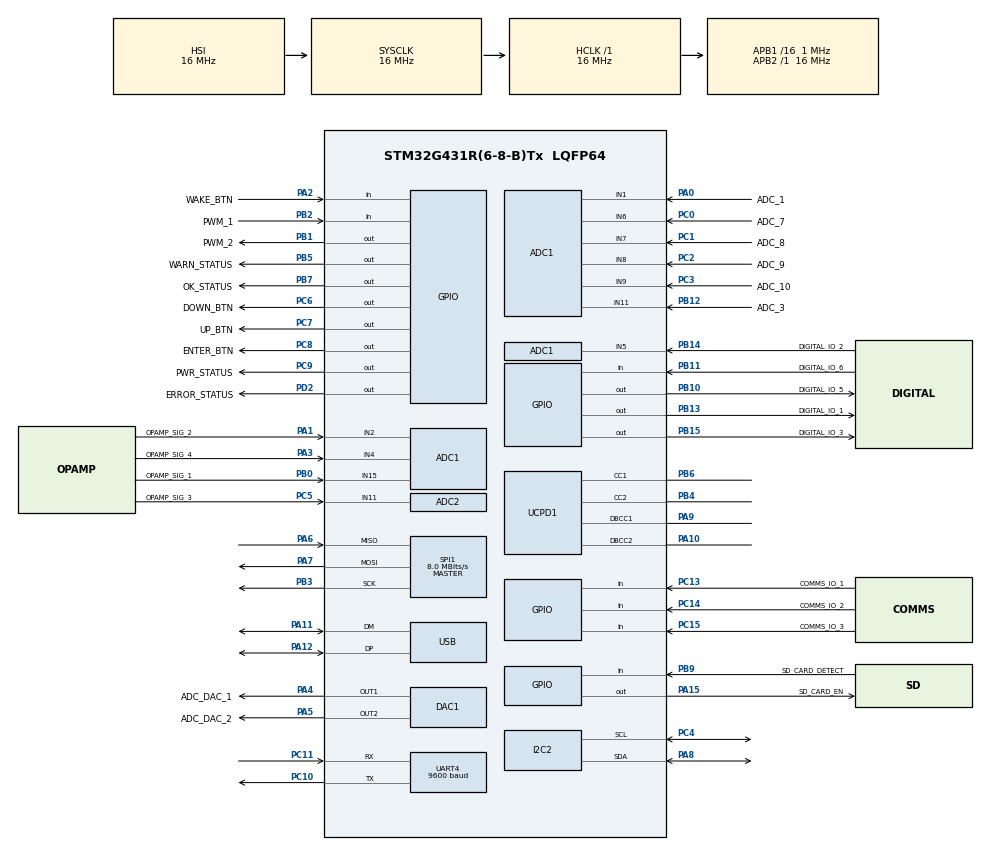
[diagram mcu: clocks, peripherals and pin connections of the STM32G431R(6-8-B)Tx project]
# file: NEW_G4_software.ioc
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ADC1.Channel-0\#ChannelRegularConversion=ADC_CHANNEL_1
ADC1.NbrOfConversionFlag=1
ADC1.OffsetNumber-0\#ChannelRegularConversion=ADC_OFFSET_NONE
ADC1.Rank-0\#ChannelRegularConversion=1
ADC1.SamplingTime-0\#ChannelRegularConversion=ADC_SAMPLETIME_2CYCLES_5
ADC1.master=1
ADC2.Channel-0\#ChannelRegularConversion=ADC_CHANNEL_11
ADC2.NbrOfConversionFlag=1
ADC2.OffsetNumber-0\#ChannelRegularConversion=ADC_OFFSET_NONE
ADC2.Rank-0\#ChannelRegularConversion=1
ADC2.SamplingTime-0\#ChannelRegularConversion=ADC_SAMPLETIME_2CYCLES_5
DAC1.DAC_Channel-DAC_OUT2=DAC_CHANNEL_2
I2C2.Timing=0x00000103
Mcu.Family=STM32G4
Mcu.Name=STM32G431R(6-8-B)Tx
Mcu.Package=LQFP64
NVIC.PriorityGroup=NVIC_PRIORITYGROUP_4
NVIC.USB_LP_IRQn=true\:0\:0\:false\:false\:true\:false\:true\:true
PA0.GPIO_Label=ADC_1
PA0.Mode=IN1-Single-Ended
PA0.Signal=ADC1_IN1
PA1.GPIO_Label=OPAMP_SIG_2
PA1.Mode=IN2-Single-Ended
PA1.Signal=ADC1_IN2
PA10.Mode=EnableDeadBattery
PA10.Signal=UCPD1_DBCC2
PA11.Mode=Device
PA11.Signal=USB_DM
PA12.Mode=Device
PA12.Signal=USB_DP
PA13.Mode=Serial_Wire
PA13.Signal=SYS_JTMS-SWDIO
PA14.Mode=Serial_Wire
PA14.Signal=SYS_JTCK-SWCLK
PA15.GPIO_Label=SD_CARD_EN
PA15.GPIO_ModeDefaultOutputPP=GPIO_MODE_OUTPUT_PP
PA15.GPIO_PuPd=GPIO_NOPULL
PA15.Signal=GPIO_Output
PA2.GPIO_Label=WAKE_BTN
PA2.Signal=GPIO_Input
PA3.GPIO_Label=OPAMP_SIG_4
PA3.Mode=IN4-Single-Ended
PA3.Signal=ADC1_IN4
PA4.GPIO_Label=ADC_DAC_1
PA4.Signal=COMP_DAC11_group
PA5.GPIO_Label=ADC_DAC_2
PA5.Signal=COMP_DAC12_group
PA6.Mode=Full_Duplex_Master
PA6.Signal=SPI1_MISO
PA7.Mode=Full_Duplex_Master
PA7.Signal=SPI1_MOSI
PA8.Mode=I2C
PA8.Signal=I2C2_SDA
PA9.Mode=EnableDeadBattery
PA9.Signal=UCPD1_DBCC1
PB0.GPIO_Label=OPAMP_SIG_1
PB0.Mode=IN15-Single-Ended
PB0.Signal=ADC1_IN15
PB1.GPIO_Label=PWM_2
PB1.Signal=GPIO_Output
PB10.GPIO_Label=DIGITAL_IO_5
PB10.Signal=GPIO_Output
PB11.GPIO_Label=DIGITAL_IO_6
PB11.Signal=GPIO_Input
PB12.GPIO_Label=ADC_3
PB12.Mode=IN11-Single-Ended
PB12.Signal=ADC1_IN11
PB13.GPIO_Label=DIGITAL_IO_1
PB13.Signal=GPIO_Output
PB14.GPIO_Label=DIGITAL_IO_2
PB14.Mode=IN5-Single-Ended
PB14.Signal=ADC1_IN5
PB15.GPIO_Label=DIGITAL_IO_3
PB15.Signal=GPIO_Output
PB2.GPIO_Label=PWM_1
PB2.Signal=GPIO_Input
PB3.Signal=SharedStack_PB3
PB3.Stacked=true
PB4.Mode=Sink_AllSignals
PB4.Signal=UCPD1_CC2
PB5.GPIO_Label=WARN_STATUS
PB5.GPIO_PuPd=GPIO_NOPULL
PB5.Signal=GPIO_Output
PB6.Mode=Sink_AllSignals
PB6.Signal=UCPD1_CC1
PB7.GPIO_Label=OK_STATUS
PB7.GPIO_ModeDefaultOutputPP=GPIO_MODE_OUTPUT_PP
PB7.GPIO_PuPd=GPIO_NOPULL
PB7.PinState=GPIO_PIN_RESET
PB7.Signal=GPIO_Output
PB9.GPIO_Label=SD_CARD_DETECT
PB9.Signal=GPIO_Input
PC0.GPIO_Label=ADC_7
PC0.Mode=IN6-Single-Ended
PC0.Signal=ADC1_IN6
PC1.GPIO_Label=ADC_8
PC1.Mode=IN7-Single-Ended
PC1.Signal=ADC1_IN7
PC10.Mode=Asynchronous
PC10.Signal=UART4_TX
PC11.Mode=Asynchronous
PC11.Signal=UART4_RX
PC13.GPIO_Label=COMMS_IO_1
PC13.Signal=GPIO_Input
PC14-OSC32_IN.GPIO_Label=COMMS_IO_2
PC14-OSC32_IN.Signal=GPIO_Input
PC15-OSC32_OUT.GPIO_Label=COMMS_IO_3
PC15-OSC32_OUT.Signal=GPIO_Input
PC2.GPIO_Label=ADC_9
PC2.Mode=IN8-Single-Ended
PC2.Signal=ADC1_IN8
PC3.GPIO_Label=ADC_10
PC3.Mode=IN9-Single-Ended
PC3.Signal=ADC1_IN9
PC4.Mode=I2C
PC4.Signal=I2C2_SCL
PC5.GPIO_Label=OPAMP_SIG_3
PC5.Mode=IN11-Single-Ended
PC5.Signal=ADC2_IN11
PC6.GPIO_Label=DOWN_BTN
PC6.Signal=GPIO_Output
PC7.GPIO_Label=UP_BTN
PC7.Signal=GPIO_Output
PC8.GPIO_Label=ENTER_BTN
PC8.Signal=GPIO_Output
PC9.GPIO_Label=PWR_STATUS
PC9.Signal=GPIO_Output
PD2.GPIO_Label=ERROR_STATUS
PD2.Signal=GPIO_Output
PF0-OSC_IN.Mode=HSE-External-Oscillator
PF0-OSC_IN.Signal=RCC_OSC_IN
PF1-OSC_OUT.Mode=HSE-External-Oscillator
PF1-OSC_OUT.Signal=RCC_OSC_OUT
ProjectManager.HeapSize=0x200
ProjectManager.StackSize=0x400
ProjectManager.TargetToolchain=STM32CubeIDE
RCC.AHBFreq_Value=16000000
RCC.APB1CLKDivider=RCC_HCLK_DIV16
RCC.APB1Freq_Value=1000000
RCC.APB1TimFreq_Value=2000000
RCC.APB2Freq_Value=16000000
RCC.APB2TimFreq_Value=16000000
RCC.CortexFreq_Value=16000000
RCC.EXTERNAL_CLOCK_VALUE=12288000
RCC.HCLKFreq_Value=16000000
RCC.HSE_VALUE=8000000
RCC.HSI48_VALUE=48000000
RCC.HSI_VALUE=16000000
RCC.LSE_VALUE=32768
RCC.PLLN=12
RCC.PLLQ=RCC_PLLQ_DIV4
RCC.SYSCLKFreq_VALUE=16000000
RCC.USBFreq_Value=48000000
RCC.VCOOutputFreq_Value=192000000
RTC.WakeUpClock-WakeUp=RTC_WAKEUPCLOCK_CK_SPRE_17BITS
RTC.WakeUpCounter-WakeUp=65535
SH.COMP_DAC11_group.0=DAC1_OUT1,DAC_OUT1
SH.COMP_DAC12_group.0=DAC1_OUT2,DAC_OUT2
SH.SharedStack_PB3.0=SPI1_SCK,Full_Duplex_Master
SH.SharedStack_PB3.1=SYS_JTDO-SWO
SPI1.CalculateBaudRate=8.0 MBits/s
SPI1.Direction=SPI_DIRECTION_2LINES
SPI1.Mode=SPI_MODE_MASTER
SPI1.VirtualType=VM_MASTER
UART4.BaudRate=9600
USB_DEVICE.CLASS_NAME_FS=CDC
USB_DEVICE.VirtualMode=Cdc
USB_DEVICE.VirtualModeFS=Cdc_FS
VP_ADC1_Vbat_Input.Mode=IN-Vbat
VP_RTC_VS_RTC_Activate.Mode=RTC_Enabled
VP_RTC_VS_RTC_WakeUp_intern.Mode=WakeUp
VP_SYS_VS_DBSignals.Mode=DisableDeadBatterySignals
VP_USB_DEVICE_VS_USB_DEVICE_CDC_FS.Mode=CDC_FS
board=custom

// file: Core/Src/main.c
/* USER CODE BEGIN Header */
/**
  ******************************************************************************
  * @file           : main.c
  * @brief          : Main program body
  ******************************************************************************
  * @attention
  *
  * Copyright (c) 2024 STMicroelectronics.
  * All rights reserved.
  *
  * This software is licensed under terms that can be found in the LICENSE file
  * in the root directory of this software component.
  * If no LICENSE file comes with this software, it is provided AS-IS.
  *
  ******************************************************************************
  */
/* USER CODE END Header */
#include "main.h"
#include "adc.h"
#include "dac.h"
#include "i2c.h"
#include "rtc.h"
#include "spi.h"
#include "usart.h"
#include "ucpd.h"
#include "usb_device.h"
#include "gpio.h"

void SystemClock_Config(void);

/* USER CODE BEGIN 0 */
#define TEMP_SENSOR_ADDR 0b0011000
/* USER CODE END 0 */

int main(void)
{

  /* MCU Configuration--------------------------------------------------------*/

  /* Reset of all peripherals, Initializes the Flash interface and the Systick. */
  HAL_Init();

  /* Configure the system clock */
  SystemClock_Config();

  /* Initialize all configured peripherals */
  MX_GPIO_Init();
  MX_ADC1_Init();
  MX_ADC2_Init();
  MX_DAC1_Init();
  MX_SPI1_Init();
  MX_UCPD1_Init();
  MX_I2C2_Init();
  MX_RTC_Init();
  MX_USB_Device_Init();
  MX_UART4_Init();
  /* USER CODE BEGIN 2 */
  int count = 0;
  char buff[128];
  uint8_t TX_Buffer = 0x05 ; // DATA to send
  uint8_t RX_Buffer [12]; // DATA to send

  /* USER CODE END 2 */

  /* Infinite loop */
  while (1)
  {

    /* USER CODE BEGIN 3 */
      HAL_I2C_Master_Transmit(&hi2c2,TEMP_SENSOR_ADDR,&TX_Buffer,1,1000); //Sending in Blocking mode
      HAL_I2C_Master_Receive(&hi2c2,TEMP_SENSOR_ADDR, RX_Buffer, 1, 1000);

      int amount_fmted = snprintf(buff, sizeof(buff), "count : %d i2c_revc %d \r\n", count++, RX_Buffer[0]);

      CDC_Transmit_FS(buff, amount_fmted);
    HAL_Delay(400);
  }
  /* USER CODE END 3 */
}

void SystemClock_Config(void)
{
  RCC_OscInitTypeDef RCC_OscInitStruct = {0};
  RCC_ClkInitTypeDef RCC_ClkInitStruct = {0};

  /** Configure the main internal regulator output voltage
  */
  HAL_PWREx_ControlVoltageScaling(PWR_REGULATOR_VOLTAGE_SCALE1);

  /** Initializes the RCC Oscillators according to the specified parameters
  * in the RCC_OscInitTypeDef structure.
  */
  RCC_OscInitStruct.OscillatorType = RCC_OSCILLATORTYPE_HSI|RCC_OSCILLATORTYPE_LSI;
  RCC_OscInitStruct.HSIState = RCC_HSI_ON;
  RCC_OscInitStruct.HSICalibrationValue = RCC_HSICALIBRATION_DEFAULT;
  RCC_OscInitStruct.LSIState = RCC_LSI_ON;
  RCC_OscInitStruct.PLL.PLLState = RCC_PLL_ON;
  RCC_OscInitStruct.PLL.PLLSource = RCC_PLLSOURCE_HSI;
  RCC_OscInitStruct.PLL.PLLM = RCC_PLLM_DIV1;
  RCC_OscInitStruct.PLL.PLLN = 12;
  RCC_OscInitStruct.PLL.PLLP = RCC_PLLP_DIV2;
  RCC_OscInitStruct.PLL.PLLQ = RCC_PLLQ_DIV4;
  RCC_OscInitStruct.PLL.PLLR = RCC_PLLR_DIV2;
  if (HAL_RCC_OscConfig(&RCC_OscInitStruct) != HAL_OK)
  {
    Error_Handler();
  }

  /** Initializes the CPU, AHB and APB buses clocks
  */
  RCC_ClkInitStruct.ClockType = RCC_CLOCKTYPE_HCLK|RCC_CLOCKTYPE_SYSCLK
                              |RCC_CLOCKTYPE_PCLK1|RCC_CLOCKTYPE_PCLK2;
  RCC_ClkInitStruct.SYSCLKSource = RCC_SYSCLKSOURCE_HSI;
  RCC_ClkInitStruct.AHBCLKDivider = RCC_SYSCLK_DIV1;
  RCC_ClkInitStruct.APB1CLKDivider = RCC_HCLK_DIV16;
  RCC_ClkInitStruct.APB2CLKDivider = RCC_HCLK_DIV1;

  if (HAL_RCC_ClockConfig(&RCC_ClkInitStruct, FLASH_LATENCY_0) != HAL_OK)
  {
    Error_Handler();
  }
}

void Error_Handler(void)
{
  __disable_irq();
  while (1)
  {
  }
}
